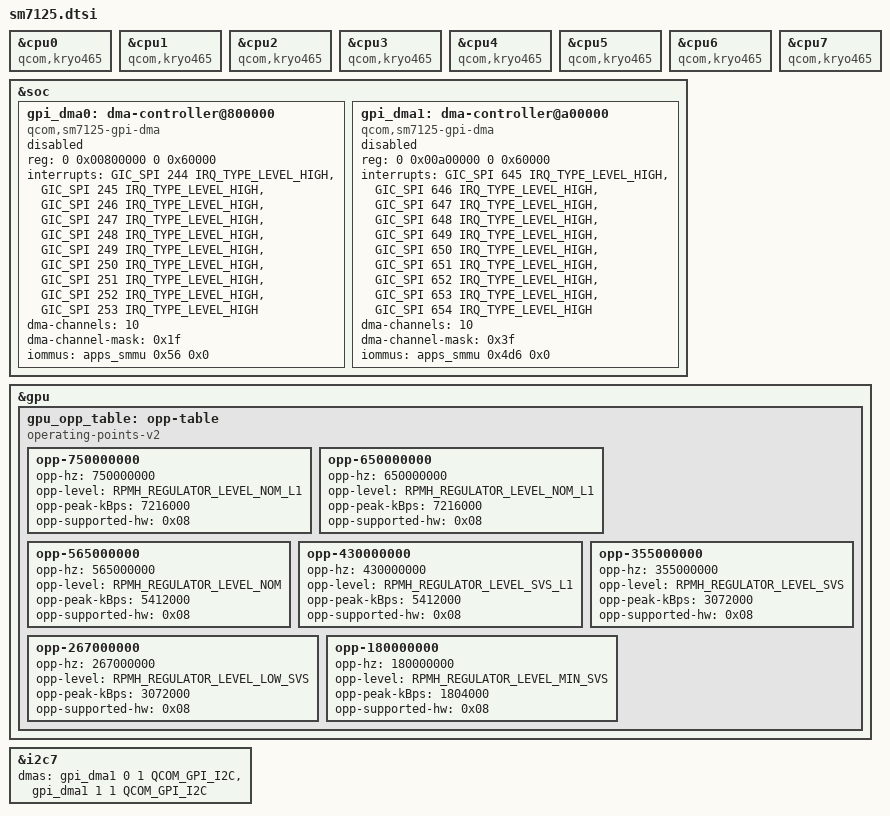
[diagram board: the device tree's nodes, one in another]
// SPDX-License-Identifier: GPL-2.0
/*
 * Copyright (c) 2021, The Linux Foundation. All rights reserved.
 */

#include <dt-bindings/dma/qcom-gpi.h>
#include "sc7180.dtsi"

/* SM7125 uses Kryo 465 instead of Kryo 468 */
&cpu0 { compatible = "qcom,kryo465"; };
&cpu1 { compatible = "qcom,kryo465"; };
&cpu2 { compatible = "qcom,kryo465"; };
&cpu3 { compatible = "qcom,kryo465"; };
&cpu4 { compatible = "qcom,kryo465"; };
&cpu5 { compatible = "qcom,kryo465"; };
&cpu6 { compatible = "qcom,kryo465"; };
&cpu7 { compatible = "qcom,kryo465"; };

&soc {
	gpi_dma0: dma-controller@800000  {
		compatible = "qcom,sm7125-gpi-dma", "qcom,sm6350-gpi-dma";
		reg = <0 0x00800000 0 0x60000>;
		interrupts = <GIC_SPI 244 IRQ_TYPE_LEVEL_HIGH>,
					<GIC_SPI 245 IRQ_TYPE_LEVEL_HIGH>,
					<GIC_SPI 246 IRQ_TYPE_LEVEL_HIGH>,
					<GIC_SPI 247 IRQ_TYPE_LEVEL_HIGH>,
					<GIC_SPI 248 IRQ_TYPE_LEVEL_HIGH>,
					<GIC_SPI 249 IRQ_TYPE_LEVEL_HIGH>,
					<GIC_SPI 250 IRQ_TYPE_LEVEL_HIGH>,
					<GIC_SPI 251 IRQ_TYPE_LEVEL_HIGH>,
					<GIC_SPI 252 IRQ_TYPE_LEVEL_HIGH>,
					<GIC_SPI 253 IRQ_TYPE_LEVEL_HIGH>;
		dma-channels = <10>;
		dma-channel-mask = <0x1f>;
		iommus = <&apps_smmu 0x56 0x0>;
		#dma-cells = <3>;
		status = "disabled";
	};

	gpi_dma1: dma-controller@a00000 {
		compatible = "qcom,sm7125-gpi-dma", "qcom,sm6350-gpi-dma";
		reg = <0 0x00a00000 0 0x60000>;
		interrupts = <GIC_SPI 645 IRQ_TYPE_LEVEL_HIGH>,
					<GIC_SPI 646 IRQ_TYPE_LEVEL_HIGH>,
					<GIC_SPI 647 IRQ_TYPE_LEVEL_HIGH>,
					<GIC_SPI 648 IRQ_TYPE_LEVEL_HIGH>,
					<GIC_SPI 649 IRQ_TYPE_LEVEL_HIGH>,
					<GIC_SPI 650 IRQ_TYPE_LEVEL_HIGH>,
					<GIC_SPI 651 IRQ_TYPE_LEVEL_HIGH>,
					<GIC_SPI 652 IRQ_TYPE_LEVEL_HIGH>,
					<GIC_SPI 653 IRQ_TYPE_LEVEL_HIGH>,
					<GIC_SPI 654 IRQ_TYPE_LEVEL_HIGH>;
		dma-channels = <10>;
		dma-channel-mask = <0x3f>;
		iommus = <&apps_smmu 0x4d6 0x0>;
		#dma-cells = <3>;
		status = "disabled";
	};
};

/delete-node/ &gpu_opp_table;
&gpu {
	gpu_opp_table: opp-table {
		compatible = "operating-points-v2";

		opp-750000000 {
			opp-hz = /bits/ 64 <750000000>;
			opp-level = <RPMH_REGULATOR_LEVEL_NOM_L1>;
			opp-peak-kBps = <7216000>;
			opp-supported-hw = <0x08>;
		};

		opp-650000000 {
			opp-hz = /bits/ 64 <650000000>;
			opp-level = <RPMH_REGULATOR_LEVEL_NOM_L1>;
			opp-peak-kBps = <7216000>;
			opp-supported-hw = <0x08>;
		};

		opp-565000000 {
			opp-hz = /bits/ 64 <565000000>;
			opp-level = <RPMH_REGULATOR_LEVEL_NOM>;
			opp-peak-kBps = <5412000>;
			opp-supported-hw = <0x08>;
		};

		opp-430000000 {
			opp-hz = /bits/ 64 <430000000>;
			opp-level = <RPMH_REGULATOR_LEVEL_SVS_L1>;
			opp-peak-kBps = <5412000>;
			opp-supported-hw = <0x08>;
		};

		opp-355000000 {
			opp-hz = /bits/ 64 <355000000>;
			opp-level = <RPMH_REGULATOR_LEVEL_SVS>;
			opp-peak-kBps = <3072000>;
			opp-supported-hw = <0x08>;
		};

		opp-267000000 {
			opp-hz = /bits/ 64 <267000000>;
			opp-level = <RPMH_REGULATOR_LEVEL_LOW_SVS>;
			opp-peak-kBps = <3072000>;
			opp-supported-hw = <0x08>;
		};

		opp-180000000 {
			opp-hz = /bits/ 64 <180000000>;
			opp-level = <RPMH_REGULATOR_LEVEL_MIN_SVS>;
			opp-peak-kBps = <1804000>;
			opp-supported-hw = <0x08>;
		};
	};
};

&i2c7 {
	dmas = <&gpi_dma1 0 1 QCOM_GPI_I2C>,
			<&gpi_dma1 1 1 QCOM_GPI_I2C>;
	dma-names = "tx", "rx";
};
